AUTOSAR XML (schema 4-2-2)
package /Components
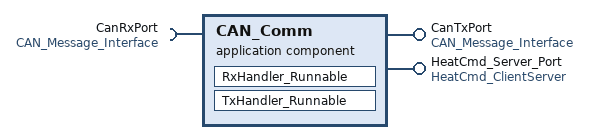
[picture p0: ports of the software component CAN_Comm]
  application sw component type CAN_Comm
    provide port CanTxPort: provided-interface=CAN_Message_Interface
    provide port HeatCmd_Server_Port: provided-interface=HeatCmd_ClientServer
    require port CanRxPort: required-interface=CAN_Message_Interface
    behavior CAN_Comm_Behavior
      data receive error event CAN_Rx_Error: start-on-event=Read_Sensors_Runnable
      data send completed event CAN_Tx_Completed: start-on-event=Read_Sensors_Runnable, event-source=Tx_Status_Access
      external trigger occurred event CAN_Frame_Received: start-on-event=Read_Sensors_Runnable
      runnable RxHandler_Runnable: minimum-start-interval=50, symbol=CAN_Comm.RxHandler
        data-receive-point-by-arguments:
          access Rx_CanFrame_Access: accessed-variable=CanRxPort.Set_Level_Command
        data-send-points:
          access Forward_Command_Access: accessed-variable=CanTxPort.Set_Level_Command
        async call CanDriver_Rx_Call: operation=CanDriver_R.RxOperation, timeout=50
      runnable TxHandler_Runnable: minimum-start-interval=1000, symbol=CAN_Comm.TxHandler
        data-receive-point-by-arguments:
          access Tx_Status_Input_Access: accessed-variable=CanTxPort.Heater_Status_Report
        data-send-points:
          access Tx_Status_Access: accessed-variable=CanTxPort.Heater_Status_Report
        async call CanDriver_Send_Call: operation=CanDriver_R.SendOperation, timeout=50
